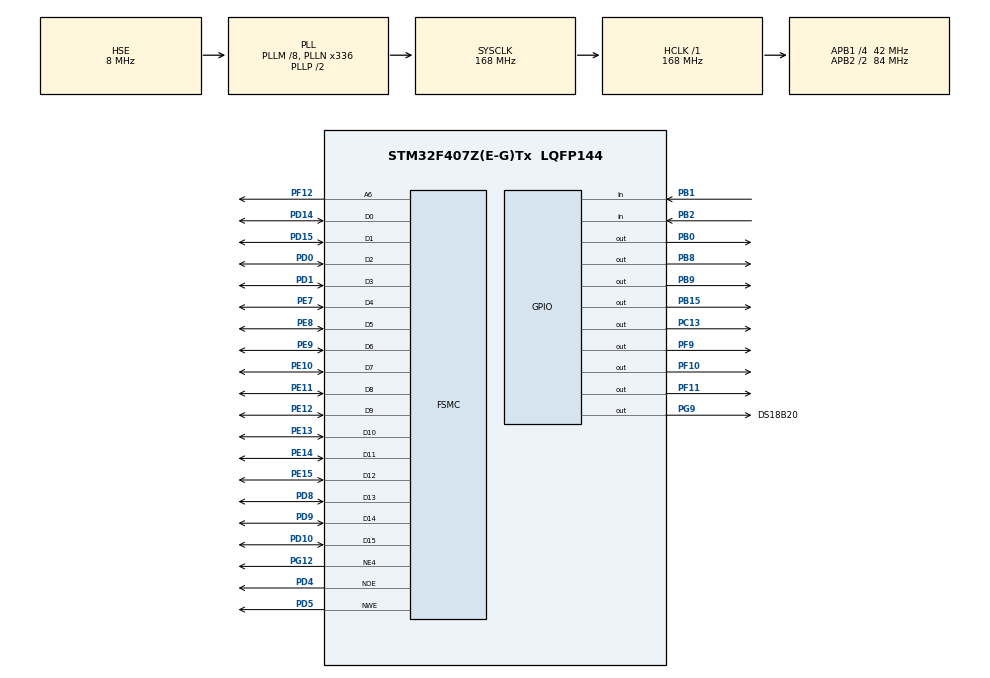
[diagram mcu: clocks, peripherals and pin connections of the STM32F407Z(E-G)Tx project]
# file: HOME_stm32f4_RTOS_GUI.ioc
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FREERTOS.Tasks01=LED_task,0,128,Start_LED_Task,Default,NULL,Static,LED_taskBuffer,LED_taskControlBlock;LCD_Task,-3,512,Start_LCD_Task,Default,NULL,Static,LCD_TaskBuffer,LCD_TaskControlBlock
FSMC.AddressSetupTime1=5
FSMC.BusTurnAroundDuration1=5
FSMC.DataSetupTime1=60
Mcu.Family=STM32F4
Mcu.Name=STM32F407Z(E-G)Tx
Mcu.Package=LQFP144
NVIC.PriorityGroup=NVIC_PRIORITYGROUP_4
NVIC.TIM2_IRQn=true\:0\:0\:false\:false\:true\:false\:false\:true
NVIC.TimeBase=TIM2_IRQn
NVIC.TimeBaseIP=TIM2
PA13.Mode=Serial_Wire
PA13.Signal=SYS_JTMS-SWDIO
PA14.Mode=Serial_Wire
PA14.Signal=SYS_JTCK-SWCLK
PB0.GPIO_PuPd=GPIO_PULLUP
PB0.GPIO_Speed=GPIO_SPEED_FREQ_HIGH
PB0.PinState=GPIO_PIN_SET
PB0.Signal=GPIO_Output
PB1.GPIO_PuPd=GPIO_PULLUP
PB1.Signal=GPIO_Input
PB15.Signal=GPIO_Output
PB2.GPIO_PuPd=GPIO_PULLUP
PB2.Signal=GPIO_Input
PB8.GPIO_PuPd=GPIO_PULLUP
PB8.GPIO_Speed=GPIO_SPEED_FREQ_MEDIUM
PB8.PinState=GPIO_PIN_SET
PB8.Signal=GPIO_Output
PB9.GPIO_PuPd=GPIO_PULLUP
PB9.GPIO_Speed=GPIO_SPEED_FREQ_MEDIUM
PB9.PinState=GPIO_PIN_SET
PB9.Signal=GPIO_Output
PC13-ANTI_TAMP.GPIO_PuPd=GPIO_PULLUP
PC13-ANTI_TAMP.PinState=GPIO_PIN_SET
PC13-ANTI_TAMP.Signal=GPIO_Output
PD0.Signal=FSMC_D2_DA2
PD1.Signal=FSMC_D3_DA3
PD10.Signal=FSMC_D15_DA15
PD14.Signal=FSMC_D0_DA0
PD15.Signal=FSMC_D1_DA1
PD4.Signal=FSMC_NOE
PD5.Signal=FSMC_NWE
PD8.Signal=FSMC_D13_DA13
PD9.Signal=FSMC_D14_DA14
PE10.Signal=FSMC_D7_DA7
PE11.Signal=FSMC_D8_DA8
PE12.Signal=FSMC_D9_DA9
PE13.Signal=FSMC_D10_DA10
PE14.Signal=FSMC_D11_DA11
PE15.Signal=FSMC_D12_DA12
PE7.Signal=FSMC_D4_DA4
PE8.Signal=FSMC_D5_DA5
PE9.Signal=FSMC_D6_DA6
PF10.Signal=GPIO_Output
PF11.GPIO_PuPd=GPIO_PULLUP
PF11.GPIO_Speed=GPIO_SPEED_FREQ_HIGH
PF11.PinState=GPIO_PIN_SET
PF11.Signal=GPIO_Output
PF12.GPIO_Speed_High_Default=GPIO_SPEED_FREQ_HIGH
PF12.Signal=FSMC_A6
PF9.Signal=GPIO_Output
PG12.Mode=NorPsramChipSelect4_1
PG12.Signal=FSMC_NE4
PG9.GPIO_Label=DS18B20
PG9.GPIO_PuPd=GPIO_PULLUP
PG9.GPIO_Speed=GPIO_SPEED_FREQ_MEDIUM
PG9.PinState=GPIO_PIN_RESET
PG9.Signal=GPIO_Output
PH0-OSC_IN.Mode=HSE-External-Oscillator
PH0-OSC_IN.Signal=RCC_OSC_IN
PH1-OSC_OUT.Mode=HSE-External-Oscillator
PH1-OSC_OUT.Signal=RCC_OSC_OUT
ProjectManager.HeapSize=0x400
ProjectManager.StackSize=0x800
ProjectManager.TargetToolchain=MDK-ARM V5
RCC.48MHZClocksFreq_Value=84000000
RCC.AHBFreq_Value=168000000
RCC.APB1CLKDivider=RCC_HCLK_DIV4
RCC.APB1Freq_Value=42000000
RCC.APB1TimFreq_Value=84000000
RCC.APB2CLKDivider=RCC_HCLK_DIV2
RCC.APB2Freq_Value=84000000
RCC.APB2TimFreq_Value=168000000
RCC.CortexFreq_Value=168000000
RCC.HCLKFreq_Value=168000000
RCC.HSE_VALUE=8000000
RCC.HSICalibrationValue=16
RCC.HSI_VALUE=16000000
RCC.LSE_VALUE=32768
RCC.PLLM=8
RCC.PLLN=336
RCC.PLLSourceVirtual=RCC_PLLSOURCE_HSE
RCC.SYSCLKFreq_VALUE=168000000
RCC.SYSCLKSource=RCC_SYSCLKSOURCE_PLLCLK
RCC.VCOOutputFreq_Value=336000000
SH.FSMC_A6.0=FSMC_A6,A6_1
SH.FSMC_D0_DA0.0=FSMC_D0,16b-d1
SH.FSMC_D10_DA10.0=FSMC_D10,16b-d1
SH.FSMC_D11_DA11.0=FSMC_D11,16b-d1
SH.FSMC_D12_DA12.0=FSMC_D12,16b-d1
SH.FSMC_D13_DA13.0=FSMC_D13,16b-d1
SH.FSMC_D14_DA14.0=FSMC_D14,16b-d1
SH.FSMC_D15_DA15.0=FSMC_D15,16b-d1
SH.FSMC_D1_DA1.0=FSMC_D1,16b-d1
SH.FSMC_D2_DA2.0=FSMC_D2,16b-d1
SH.FSMC_D3_DA3.0=FSMC_D3,16b-d1
SH.FSMC_D4_DA4.0=FSMC_D4,16b-d1
SH.FSMC_D5_DA5.0=FSMC_D5,16b-d1
SH.FSMC_D6_DA6.0=FSMC_D6,16b-d1
SH.FSMC_D7_DA7.0=FSMC_D7,16b-d1
SH.FSMC_D8_DA8.0=FSMC_D8,16b-d1
SH.FSMC_D9_DA9.0=FSMC_D9,16b-d1
SH.FSMC_NOE.0=FSMC_NOE,Lcd1
SH.FSMC_NWE.0=FSMC_NWE,Lcd1
VP_CRC_VS_CRC.Mode=CRC_Activate
VP_FREERTOS_VS_CMSIS_V1.Mode=CMSIS_V1
VP_SYS_VS_tim2.Mode=TIM2
board=custom

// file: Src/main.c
/* USER CODE BEGIN Header */
/**
  ******************************************************************************
  * @file           : main.c
  * @brief          : Main program body
  ******************************************************************************
  * @attention
  *
  * <h2><center>&copy; Copyright (c) 2019 STMicroelectronics.
  * All rights reserved.</center></h2>
  *
  * This software component is licensed by ST under Ultimate Liberty license
  * SLA0044, the "License"; You may not use this file except in compliance with
  * the License. You may obtain a copy of the License at:
  *                             www.st.com/SLA0044
  *
  ******************************************************************************
  */
/* USER CODE END Header */

#include "main.h"
#include "cmsis_os.h"
#include "crc.h"
#include "gpio.h"
#include "fsmc.h"

/* USER CODE BEGIN Includes */
#include "lcd_config.h"
#include "touch.h"
#include "GUI.h"

/* USER CODE END Includes */

void SystemClock_Config(void);
void MX_FREERTOS_Init(void);

int main(void)
{

  /* MCU Configuration--------------------------------------------------------*/

  /* Reset of all peripherals, Initializes the Flash interface and the Systick. */
  HAL_Init();

  /* Configure the system clock */
  SystemClock_Config();

  /* Initialize all configured peripherals */
  MX_GPIO_Init();
  MX_FSMC_Init();
  MX_CRC_Init();
  /* USER CODE BEGIN 2 */
	//delay_init(168);
	LCD_Config_Init();
	TP_Init();
//	GUI_Init();

  /* USER CODE END 2 */

  /* Call init function for freertos objects (in freertos.c) */
  MX_FREERTOS_Init();

  /* Start scheduler */
  osKernelStart();

  /* We should never get here as control is now taken by the scheduler */

  /* Infinite loop */
  while (1)
  {

  }
}

void SystemClock_Config(void)
{
  RCC_OscInitTypeDef RCC_OscInitStruct = {0};
  RCC_ClkInitTypeDef RCC_ClkInitStruct = {0};

  /** Configure the main internal regulator output voltage
  */
  __HAL_RCC_PWR_CLK_ENABLE();
  __HAL_PWR_VOLTAGESCALING_CONFIG(PWR_REGULATOR_VOLTAGE_SCALE1);
  /** Initializes the CPU, AHB and APB busses clocks
  */
  RCC_OscInitStruct.OscillatorType = RCC_OSCILLATORTYPE_HSE;
  RCC_OscInitStruct.HSEState = RCC_HSE_ON;
  RCC_OscInitStruct.PLL.PLLState = RCC_PLL_ON;
  RCC_OscInitStruct.PLL.PLLSource = RCC_PLLSOURCE_HSE;
  RCC_OscInitStruct.PLL.PLLM = 8;
  RCC_OscInitStruct.PLL.PLLN = 336;
  RCC_OscInitStruct.PLL.PLLP = RCC_PLLP_DIV2;
  RCC_OscInitStruct.PLL.PLLQ = 4;
  if (HAL_RCC_OscConfig(&RCC_OscInitStruct) != HAL_OK)
  {
    Error_Handler();
  }
  /** Initializes the CPU, AHB and APB busses clocks
  */
  RCC_ClkInitStruct.ClockType = RCC_CLOCKTYPE_HCLK|RCC_CLOCKTYPE_SYSCLK
                              |RCC_CLOCKTYPE_PCLK1|RCC_CLOCKTYPE_PCLK2;
  RCC_ClkInitStruct.SYSCLKSource = RCC_SYSCLKSOURCE_PLLCLK;
  RCC_ClkInitStruct.AHBCLKDivider = RCC_SYSCLK_DIV1;
  RCC_ClkInitStruct.APB1CLKDivider = RCC_HCLK_DIV4;
  RCC_ClkInitStruct.APB2CLKDivider = RCC_HCLK_DIV2;

  if (HAL_RCC_ClockConfig(&RCC_ClkInitStruct, FLASH_LATENCY_5) != HAL_OK)
  {
    Error_Handler();
  }
}

void HAL_TIM_PeriodElapsedCallback(TIM_HandleTypeDef *htim)
{
  if (htim->Instance == TIM2) {
    HAL_IncTick();
  }
}

void Error_Handler(void)
{
}

/************************ (C) COPYRIGHT STMicroelectronics *****END OF FILE****/
